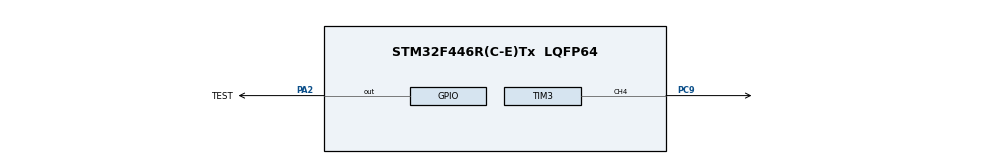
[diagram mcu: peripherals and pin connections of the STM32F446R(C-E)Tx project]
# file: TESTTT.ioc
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Mcu.Family=STM32F4
Mcu.Name=STM32F446R(C-E)Tx
Mcu.Package=LQFP64
NVIC.PriorityGroup=NVIC_PRIORITYGROUP_4
PA13.Mode=Trace_Asynchronous_SW
PA13.Signal=SYS_JTMS-SWDIO
PA14.Mode=Trace_Asynchronous_SW
PA14.Signal=SYS_JTCK-SWCLK
PA2.GPIO_Label=TEST
PA2.Signal=GPIO_Output
PB3.Mode=Trace_Asynchronous_SW
PB3.Signal=SYS_JTDO-SWO
PC9.Signal=S_TIM3_CH4
PH0-OSC_IN.Mode=HSE-External-Oscillator
PH0-OSC_IN.Signal=RCC_OSC_IN
PH1-OSC_OUT.Mode=HSE-External-Oscillator
PH1-OSC_OUT.Signal=RCC_OSC_OUT
ProjectManager.HeapSize=0x200
ProjectManager.StackSize=0x400
ProjectManager.TargetToolchain=STM32CubeIDE
RCC.CortexFreq_Value=16000000
RCC.USBFreq_Value=96000000
RCC.VCOOutputFreq_Value=192000000
SH.S_TIM3_CH4.0=TIM3_CH4,PWM Generation4 CH4
TIM3.Channel-PWM\ Generation4\ CH4=TIM_CHANNEL_4
TIM3.Period=39999
TIM3.Prescaler=79
TIM3.Pulse-PWM\ Generation4\ CH4=30
board=custom

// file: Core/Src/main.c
/* USER CODE BEGIN Header */
/**
  ******************************************************************************
  * @file           : main.c
  * @brief          : Main program body
  ******************************************************************************
  * @attention
  *
  * Copyright (c) 2026 STMicroelectronics.
  * All rights reserved.
  *
  * This software is licensed under terms that can be found in the LICENSE file
  * in the root directory of this software component.
  * If no LICENSE file comes with this software, it is provided AS-IS.
  *
  ******************************************************************************
  */
/* USER CODE END Header */
#include "main.h"

TIM_HandleTypeDef htim3;

void SystemClock_Config(void);
static void MX_GPIO_Init(void);
static void MX_TIM3_Init(void);

int main(void)
{

  /* MCU Configuration--------------------------------------------------------*/

  /* Reset of all peripherals, Initializes the Flash interface and the Systick. */
  HAL_Init();

  /* Configure the system clock */
  SystemClock_Config();

  /* Initialize all configured peripherals */
  MX_GPIO_Init();
  MX_TIM3_Init();
  /* USER CODE BEGIN 2 */
	HAL_TIM_PWM_Start(&htim3, TIM_CHANNEL_4);

  /* USER CODE END 2 */

  /* Infinite loop */
  /* USER CODE BEGIN WHILE */
  while (1)
  {
	  HAL_GPIO_WritePin(TEST_GPIO_Port, TEST_Pin, GPIO_PIN_RESET);

    /* USER CODE END WHILE */

  }
}

void SystemClock_Config(void)
{
  RCC_OscInitTypeDef RCC_OscInitStruct = {0};
  RCC_ClkInitTypeDef RCC_ClkInitStruct = {0};

  /** Configure the main internal regulator output voltage
  */
  __HAL_RCC_PWR_CLK_ENABLE();
  __HAL_PWR_VOLTAGESCALING_CONFIG(PWR_REGULATOR_VOLTAGE_SCALE3);

  /** Initializes the RCC Oscillators according to the specified parameters
  * in the RCC_OscInitTypeDef structure.
  */
  RCC_OscInitStruct.OscillatorType = RCC_OSCILLATORTYPE_HSI;
  RCC_OscInitStruct.HSIState = RCC_HSI_ON;
  RCC_OscInitStruct.HSICalibrationValue = RCC_HSICALIBRATION_DEFAULT;
  RCC_OscInitStruct.PLL.PLLState = RCC_PLL_NONE;
  if (HAL_RCC_OscConfig(&RCC_OscInitStruct) != HAL_OK)
  {
    Error_Handler();
  }

  /** Initializes the CPU, AHB and APB buses clocks
  */
  RCC_ClkInitStruct.ClockType = RCC_CLOCKTYPE_HCLK|RCC_CLOCKTYPE_SYSCLK
                              |RCC_CLOCKTYPE_PCLK1|RCC_CLOCKTYPE_PCLK2;
  RCC_ClkInitStruct.SYSCLKSource = RCC_SYSCLKSOURCE_HSI;
  RCC_ClkInitStruct.AHBCLKDivider = RCC_SYSCLK_DIV1;
  RCC_ClkInitStruct.APB1CLKDivider = RCC_HCLK_DIV1;
  RCC_ClkInitStruct.APB2CLKDivider = RCC_HCLK_DIV1;

  if (HAL_RCC_ClockConfig(&RCC_ClkInitStruct, FLASH_LATENCY_0) != HAL_OK)
  {
    Error_Handler();
  }
}

static void MX_TIM3_Init(void)
{

  TIM_MasterConfigTypeDef sMasterConfig = {0};
  TIM_OC_InitTypeDef sConfigOC = {0};

  htim3.Instance = TIM3;
  htim3.Init.Prescaler = 79;
  htim3.Init.CounterMode = TIM_COUNTERMODE_UP;
  htim3.Init.Period = 39999;
  htim3.Init.ClockDivision = TIM_CLOCKDIVISION_DIV1;
  htim3.Init.AutoReloadPreload = TIM_AUTORELOAD_PRELOAD_DISABLE;
  if (HAL_TIM_PWM_Init(&htim3) != HAL_OK)
  {
    Error_Handler();
  }
  sMasterConfig.MasterOutputTrigger = TIM_TRGO_RESET;
  sMasterConfig.MasterSlaveMode = TIM_MASTERSLAVEMODE_DISABLE;
  if (HAL_TIMEx_MasterConfigSynchronization(&htim3, &sMasterConfig) != HAL_OK)
  {
    Error_Handler();
  }
  sConfigOC.OCMode = TIM_OCMODE_PWM1;
  sConfigOC.Pulse = 30;
  sConfigOC.OCPolarity = TIM_OCPOLARITY_HIGH;
  sConfigOC.OCFastMode = TIM_OCFAST_DISABLE;
  if (HAL_TIM_PWM_ConfigChannel(&htim3, &sConfigOC, TIM_CHANNEL_4) != HAL_OK)
  {
    Error_Handler();
  }
  HAL_TIM_MspPostInit(&htim3);

}

static void MX_GPIO_Init(void)
{
  GPIO_InitTypeDef GPIO_InitStruct = {0};

  /* GPIO Ports Clock Enable */
  __HAL_RCC_GPIOH_CLK_ENABLE();
  __HAL_RCC_GPIOA_CLK_ENABLE();
  __HAL_RCC_GPIOC_CLK_ENABLE();
  __HAL_RCC_GPIOB_CLK_ENABLE();

  /*Configure GPIO pin Output Level */
  HAL_GPIO_WritePin(TEST_GPIO_Port, TEST_Pin, GPIO_PIN_RESET);

  /*Configure GPIO pin : TEST_Pin */
  GPIO_InitStruct.Pin = TEST_Pin;
  GPIO_InitStruct.Mode = GPIO_MODE_OUTPUT_PP;
  GPIO_InitStruct.Pull = GPIO_NOPULL;
  GPIO_InitStruct.Speed = GPIO_SPEED_FREQ_LOW;
  HAL_GPIO_Init(TEST_GPIO_Port, &GPIO_InitStruct);

}

void Error_Handler(void)
{
  __disable_irq();
  while (1)
  {
  }
}
